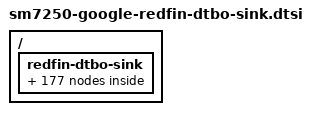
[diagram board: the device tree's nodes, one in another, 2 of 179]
// SPDX-License-Identifier: GPL-2.0-only
/*
 * Sink for the stock redfin dtbo overlays. Generated by
 * scripts/gen-dtbo-sink.py from firmware/dtbo.img; do not edit.
 *
 * Every label the 36 overlays reference (177 names, the union of
 * their __fixups__) points at an empty node under /redfin-dtbo-sink, so
 * whichever overlay the bootloader applies lands there. No compatible:
 * Linux creates no devices below it. Hand-written __symbols__ (no dtc -@):
 * real mainline nodes are never exported, so the overlay cannot touch
 * them even where label names overlap (tlmm, soc, spmi_bus, ...).
 * docs/research/mainline-boot.md, section 1.3.
 */

/ {
	redfin-dtbo-sink {
		/* Referenced so dtc gives every sink node a phandle: libfdt's
		 * fixup step needs one on each target. */
		sink-refs = <&sink_spmi_bus &sink_rpmhcc &sink_thermal_zones &sink_usb2_phy0 &sink_pm8150_l2 &sink_usb0 &sink_eud &sink_usb_qmp_dp_phy &sink_mdss_mdp &sink_CPU0 &sink_CPU6 &sink_CPU7 &sink_cpu1_isolate &sink_cpu2_isolate &sink_cpu3_isolate &sink_cpu4_isolate &sink_cpu5_isolate &sink_cpu6_isolate &sink_cpu7_isolate &sink_q6core &sink_lpass_core_hw_vote &sink_lpass_audio_hw_vote &sink_bolero &sink_intc &sink_pdc &sink_S4A &sink_BOB &sink_lito_snd &sink_stub_codec &sink_audio_apr &sink_soc &sink_spkr_1_sd_n_active &sink_spkr_1_sd_n_sleep &sink_spkr_2_sd_n_active &sink_spkr_2_sd_n_sleep &sink_wcd938x_reset_active &sink_wcd938x_reset_sleep &sink_va_cdc_dma_0_tx &sink_adsp_loader &sink_adsp_variant &sink_dai_dp &sink_dai_dp1 &sink_dai_mi2s0 &sink_dai_mi2s1 &sink_dai_mi2s2 &sink_dai_mi2s3 &sink_dai_mi2s4 &sink_dai_mi2s5 &sink_dai_pri_auxpcm &sink_dai_sec_auxpcm &sink_dai_tert_auxpcm &sink_dai_quat_auxpcm &sink_dai_quin_auxpcm &sink_dai_sen_auxpcm &sink_afe_pcm_rx &sink_afe_pcm_tx &sink_afe_proxy_rx &sink_afe_proxy_tx &sink_incall_record_rx &sink_incall_record_tx &sink_incall_music_rx &sink_incall_music_2_rx &sink_proxy_rx &sink_proxy_tx &sink_usb_audio_rx &sink_usb_audio_tx &sink_sb_7_rx &sink_sb_7_tx &sink_sb_8_tx &sink_dai_pri_tdm_rx_0 &sink_dai_pri_tdm_tx_0 &sink_dai_sec_tdm_rx_0 &sink_dai_sec_tdm_tx_0 &sink_dai_tert_tdm_rx_0 &sink_dai_tert_tdm_tx_0 &sink_dai_quat_tdm_rx_0 &sink_dai_quat_tdm_tx_0 &sink_dai_quin_tdm_rx_0 &sink_dai_quin_tdm_tx_0 &sink_dai_sen_tdm_rx_0 &sink_dai_sen_tdm_tx_0 &sink_wsa_cdc_dma_0_rx &sink_wsa_cdc_dma_0_tx &sink_wsa_cdc_dma_1_rx &sink_wsa_cdc_dma_1_tx &sink_wsa_cdc_dma_2_tx &sink_va_cdc_dma_1_tx &sink_va_cdc_dma_2_tx &sink_rx_cdc_dma_0_rx &sink_tx_cdc_dma_0_tx &sink_rx_cdc_dma_1_rx &sink_tx_cdc_dma_1_tx &sink_rx_cdc_dma_2_rx &sink_tx_cdc_dma_2_tx &sink_rx_cdc_dma_3_rx &sink_tx_cdc_dma_3_tx &sink_rx_cdc_dma_4_rx &sink_tx_cdc_dma_4_tx &sink_rx_cdc_dma_5_rx &sink_tx_cdc_dma_5_tx &sink_rx_cdc_dma_6_rx &sink_rx_cdc_dma_7_rx &sink_afe_loopback_tx &sink_qupv3_se7_i2c &sink_tlmm &sink_tdm_pri_tx &sink_qupv3_se4_spi &sink_tdm_quin_rx &sink_tdm_quin_tx &sink_qupv3_se9_i2c &sink_mdss_dsi0 &sink_mdss_dsi1 &sink_mdss_dsi_phy0 &sink_mdss_dsi_phy1 &sink_mdss_dsi0_pll &sink_mdss_dsi1_pll &sink_dispcc &sink_gcc &sink_sde_te_active &sink_sde_te_suspend &sink_L1C &sink_L16A &sink_sde_te1_active &sink_sde_te1_suspend &sink_sde_dp &sink_fsa4480 &sink_sde_dp_usbplug_cc_active &sink_sde_dp_usbplug_cc_suspend &sink_sde_rscc &sink_modem_wlan_mem &sink_reserved_memory &sink_qupv3_se7_i2c_active &sink_qupv3_se6_spi &sink_qupv3_se0_spi &sink_qupv3_se0_spi_active &sink_apps_rsc &sink_msm_gpu &sink_tsens0 &sink_aliases &sink_ufsphy_mem &sink_pm8150_l5 &sink_pm8150_l9 &sink_ufshc_mem &sink_ufs_phy_gdsc &sink_pm8150a_l7 &sink_pm8150_s4 &sink_sdhc_1 &sink_sdc1_clk_on &sink_sdc1_cmd_on &sink_sdc1_data_on &sink_sdc1_rclk_on &sink_sdc1_clk_off &sink_sdc1_cmd_off &sink_sdc1_data_off &sink_sdc1_rclk_off &sink_sdhc_2 &sink_pm8150a_l9 &sink_pm8150a_l6 &sink_sdc2_clk_on &sink_sdc2_cmd_on &sink_sdc2_data_on &sink_sdc2_cd_on &sink_sdc2_clk_off &sink_sdc2_cmd_off &sink_sdc2_data_off &sink_sdc2_cd_off &sink_msm_poweroff &sink_pm8150_l17 &sink_qupv3_se0_i2c &sink_qupv3_se11_i2c &sink_cam_cci0 &sink_titan_top_gdsc &sink_camcc &sink_cam_cci1 &sink_pm8150_l13 &sink_cci1_active &sink_cci1_suspend>;

		sink_spmi_bus: spmi-bus {};
		sink_rpmhcc: rpmhcc {};
		sink_thermal_zones: thermal-zones {};
		sink_usb2_phy0: usb2-phy0 {};
		sink_pm8150_l2: pm8150-l2 {};
		sink_usb0: usb0 {};
		sink_eud: eud {};
		sink_usb_qmp_dp_phy: usb-qmp-dp-phy {};
		sink_mdss_mdp: mdss-mdp {};
		sink_CPU0: cpu0 {};
		sink_CPU6: cpu6 {};
		sink_CPU7: cpu7 {};
		sink_cpu1_isolate: cpu1-isolate {};
		sink_cpu2_isolate: cpu2-isolate {};
		sink_cpu3_isolate: cpu3-isolate {};
		sink_cpu4_isolate: cpu4-isolate {};
		sink_cpu5_isolate: cpu5-isolate {};
		sink_cpu6_isolate: cpu6-isolate {};
		sink_cpu7_isolate: cpu7-isolate {};
		sink_q6core: q6core {};
		sink_lpass_core_hw_vote: lpass-core-hw-vote {};
		sink_lpass_audio_hw_vote: lpass-audio-hw-vote {};
		sink_bolero: bolero {};
		sink_intc: intc {};
		sink_pdc: pdc {};
		sink_S4A: s4a {};
		sink_BOB: bob {};
		sink_lito_snd: lito-snd {};
		sink_stub_codec: stub-codec {};
		sink_audio_apr: audio-apr {};
		sink_soc: soc {};
		sink_spkr_1_sd_n_active: spkr-1-sd-n-active {};
		sink_spkr_1_sd_n_sleep: spkr-1-sd-n-sleep {};
		sink_spkr_2_sd_n_active: spkr-2-sd-n-active {};
		sink_spkr_2_sd_n_sleep: spkr-2-sd-n-sleep {};
		sink_wcd938x_reset_active: wcd938x-reset-active {};
		sink_wcd938x_reset_sleep: wcd938x-reset-sleep {};
		sink_va_cdc_dma_0_tx: va-cdc-dma-0-tx {};
		sink_adsp_loader: adsp-loader {};
		sink_adsp_variant: adsp-variant {};
		sink_dai_dp: dai-dp {};
		sink_dai_dp1: dai-dp1 {};
		sink_dai_mi2s0: dai-mi2s0 {};
		sink_dai_mi2s1: dai-mi2s1 {};
		sink_dai_mi2s2: dai-mi2s2 {};
		sink_dai_mi2s3: dai-mi2s3 {};
		sink_dai_mi2s4: dai-mi2s4 {};
		sink_dai_mi2s5: dai-mi2s5 {};
		sink_dai_pri_auxpcm: dai-pri-auxpcm {};
		sink_dai_sec_auxpcm: dai-sec-auxpcm {};
		sink_dai_tert_auxpcm: dai-tert-auxpcm {};
		sink_dai_quat_auxpcm: dai-quat-auxpcm {};
		sink_dai_quin_auxpcm: dai-quin-auxpcm {};
		sink_dai_sen_auxpcm: dai-sen-auxpcm {};
		sink_afe_pcm_rx: afe-pcm-rx {};
		sink_afe_pcm_tx: afe-pcm-tx {};
		sink_afe_proxy_rx: afe-proxy-rx {};
		sink_afe_proxy_tx: afe-proxy-tx {};
		sink_incall_record_rx: incall-record-rx {};
		sink_incall_record_tx: incall-record-tx {};
		sink_incall_music_rx: incall-music-rx {};
		sink_incall_music_2_rx: incall-music-2-rx {};
		sink_proxy_rx: proxy-rx {};
		sink_proxy_tx: proxy-tx {};
		sink_usb_audio_rx: usb-audio-rx {};
		sink_usb_audio_tx: usb-audio-tx {};
		sink_sb_7_rx: sb-7-rx {};
		sink_sb_7_tx: sb-7-tx {};
		sink_sb_8_tx: sb-8-tx {};
		sink_dai_pri_tdm_rx_0: dai-pri-tdm-rx-0 {};
		sink_dai_pri_tdm_tx_0: dai-pri-tdm-tx-0 {};
		sink_dai_sec_tdm_rx_0: dai-sec-tdm-rx-0 {};
		sink_dai_sec_tdm_tx_0: dai-sec-tdm-tx-0 {};
		sink_dai_tert_tdm_rx_0: dai-tert-tdm-rx-0 {};
		sink_dai_tert_tdm_tx_0: dai-tert-tdm-tx-0 {};
		sink_dai_quat_tdm_rx_0: dai-quat-tdm-rx-0 {};
		sink_dai_quat_tdm_tx_0: dai-quat-tdm-tx-0 {};
		sink_dai_quin_tdm_rx_0: dai-quin-tdm-rx-0 {};
		sink_dai_quin_tdm_tx_0: dai-quin-tdm-tx-0 {};
		sink_dai_sen_tdm_rx_0: dai-sen-tdm-rx-0 {};
		sink_dai_sen_tdm_tx_0: dai-sen-tdm-tx-0 {};
		sink_wsa_cdc_dma_0_rx: wsa-cdc-dma-0-rx {};
		sink_wsa_cdc_dma_0_tx: wsa-cdc-dma-0-tx {};
		sink_wsa_cdc_dma_1_rx: wsa-cdc-dma-1-rx {};
		sink_wsa_cdc_dma_1_tx: wsa-cdc-dma-1-tx {};
		sink_wsa_cdc_dma_2_tx: wsa-cdc-dma-2-tx {};
		sink_va_cdc_dma_1_tx: va-cdc-dma-1-tx {};
		sink_va_cdc_dma_2_tx: va-cdc-dma-2-tx {};
		sink_rx_cdc_dma_0_rx: rx-cdc-dma-0-rx {};
		sink_tx_cdc_dma_0_tx: tx-cdc-dma-0-tx {};
		sink_rx_cdc_dma_1_rx: rx-cdc-dma-1-rx {};
		sink_tx_cdc_dma_1_tx: tx-cdc-dma-1-tx {};
		sink_rx_cdc_dma_2_rx: rx-cdc-dma-2-rx {};
		sink_tx_cdc_dma_2_tx: tx-cdc-dma-2-tx {};
		sink_rx_cdc_dma_3_rx: rx-cdc-dma-3-rx {};
		sink_tx_cdc_dma_3_tx: tx-cdc-dma-3-tx {};
		sink_rx_cdc_dma_4_rx: rx-cdc-dma-4-rx {};
		sink_tx_cdc_dma_4_tx: tx-cdc-dma-4-tx {};
		sink_rx_cdc_dma_5_rx: rx-cdc-dma-5-rx {};
		sink_tx_cdc_dma_5_tx: tx-cdc-dma-5-tx {};
		sink_rx_cdc_dma_6_rx: rx-cdc-dma-6-rx {};
		sink_rx_cdc_dma_7_rx: rx-cdc-dma-7-rx {};
		sink_afe_loopback_tx: afe-loopback-tx {};
		sink_qupv3_se7_i2c: qupv3-se7-i2c {};
		sink_tlmm: tlmm {};
		sink_tdm_pri_tx: tdm-pri-tx {};
		sink_qupv3_se4_spi: qupv3-se4-spi {};
		sink_tdm_quin_rx: tdm-quin-rx {};
		sink_tdm_quin_tx: tdm-quin-tx {};
		sink_qupv3_se9_i2c: qupv3-se9-i2c {};
		sink_mdss_dsi0: mdss-dsi0 {};
		sink_mdss_dsi1: mdss-dsi1 {};
		sink_mdss_dsi_phy0: mdss-dsi-phy0 {};
		sink_mdss_dsi_phy1: mdss-dsi-phy1 {};
		sink_mdss_dsi0_pll: mdss-dsi0-pll {};
		sink_mdss_dsi1_pll: mdss-dsi1-pll {};
		sink_dispcc: dispcc {};
		sink_gcc: gcc {};
		sink_sde_te_active: sde-te-active {};
		sink_sde_te_suspend: sde-te-suspend {};
		sink_L1C: l1c {};
		sink_L16A: l16a {};
		sink_sde_te1_active: sde-te1-active {};
		sink_sde_te1_suspend: sde-te1-suspend {};
		sink_sde_dp: sde-dp {};
		sink_fsa4480: fsa4480 {};
		sink_sde_dp_usbplug_cc_active: sde-dp-usbplug-cc-active {};
		sink_sde_dp_usbplug_cc_suspend: sde-dp-usbplug-cc-suspend {};
		sink_sde_rscc: sde-rscc {};
		sink_modem_wlan_mem: modem-wlan-mem {};
		sink_reserved_memory: reserved-memory {};
		sink_qupv3_se7_i2c_active: qupv3-se7-i2c-active {};
		sink_qupv3_se6_spi: qupv3-se6-spi {};
		sink_qupv3_se0_spi: qupv3-se0-spi {};
		sink_qupv3_se0_spi_active: qupv3-se0-spi-active {};
		sink_apps_rsc: apps-rsc {};
		sink_msm_gpu: msm-gpu {};
		sink_tsens0: tsens0 {};
		sink_aliases: aliases {};
		sink_ufsphy_mem: ufsphy-mem {};
		sink_pm8150_l5: pm8150-l5 {};
		sink_pm8150_l9: pm8150-l9 {};
		sink_ufshc_mem: ufshc-mem {};
		sink_ufs_phy_gdsc: ufs-phy-gdsc {};
		sink_pm8150a_l7: pm8150a-l7 {};
		sink_pm8150_s4: pm8150-s4 {};
		sink_sdhc_1: sdhc-1 {};
		sink_sdc1_clk_on: sdc1-clk-on {};
		sink_sdc1_cmd_on: sdc1-cmd-on {};
		sink_sdc1_data_on: sdc1-data-on {};
		sink_sdc1_rclk_on: sdc1-rclk-on {};
		sink_sdc1_clk_off: sdc1-clk-off {};
		sink_sdc1_cmd_off: sdc1-cmd-off {};
		sink_sdc1_data_off: sdc1-data-off {};
		sink_sdc1_rclk_off: sdc1-rclk-off {};
		sink_sdhc_2: sdhc-2 {};
		sink_pm8150a_l9: pm8150a-l9 {};
		sink_pm8150a_l6: pm8150a-l6 {};
		sink_sdc2_clk_on: sdc2-clk-on {};
		sink_sdc2_cmd_on: sdc2-cmd-on {};
		sink_sdc2_data_on: sdc2-data-on {};
		sink_sdc2_cd_on: sdc2-cd-on {};
		sink_sdc2_clk_off: sdc2-clk-off {};
		sink_sdc2_cmd_off: sdc2-cmd-off {};
		sink_sdc2_data_off: sdc2-data-off {};
		sink_sdc2_cd_off: sdc2-cd-off {};
		sink_msm_poweroff: msm-poweroff {};
		sink_pm8150_l17: pm8150-l17 {};
		sink_qupv3_se0_i2c: qupv3-se0-i2c {};
		sink_qupv3_se11_i2c: qupv3-se11-i2c {};
		sink_cam_cci0: cam-cci0 {};
		sink_titan_top_gdsc: titan-top-gdsc {};
		sink_camcc: camcc {};
		sink_cam_cci1: cam-cci1 {};
		sink_pm8150_l13: pm8150-l13 {};
		sink_cci1_active: cci1-active {};
		sink_cci1_suspend: cci1-suspend {};
	};

	__symbols__ {
		spmi_bus = "/redfin-dtbo-sink/spmi-bus";
		rpmhcc = "/redfin-dtbo-sink/rpmhcc";
		thermal_zones = "/redfin-dtbo-sink/thermal-zones";
		usb2_phy0 = "/redfin-dtbo-sink/usb2-phy0";
		pm8150_l2 = "/redfin-dtbo-sink/pm8150-l2";
		usb0 = "/redfin-dtbo-sink/usb0";
		eud = "/redfin-dtbo-sink/eud";
		usb_qmp_dp_phy = "/redfin-dtbo-sink/usb-qmp-dp-phy";
		mdss_mdp = "/redfin-dtbo-sink/mdss-mdp";
		CPU0 = "/redfin-dtbo-sink/cpu0";
		CPU6 = "/redfin-dtbo-sink/cpu6";
		CPU7 = "/redfin-dtbo-sink/cpu7";
		cpu1_isolate = "/redfin-dtbo-sink/cpu1-isolate";
		cpu2_isolate = "/redfin-dtbo-sink/cpu2-isolate";
		cpu3_isolate = "/redfin-dtbo-sink/cpu3-isolate";
		cpu4_isolate = "/redfin-dtbo-sink/cpu4-isolate";
		cpu5_isolate = "/redfin-dtbo-sink/cpu5-isolate";
		cpu6_isolate = "/redfin-dtbo-sink/cpu6-isolate";
		cpu7_isolate = "/redfin-dtbo-sink/cpu7-isolate";
		q6core = "/redfin-dtbo-sink/q6core";
		lpass_core_hw_vote = "/redfin-dtbo-sink/lpass-core-hw-vote";
		lpass_audio_hw_vote = "/redfin-dtbo-sink/lpass-audio-hw-vote";
		bolero = "/redfin-dtbo-sink/bolero";
		intc = "/redfin-dtbo-sink/intc";
		pdc = "/redfin-dtbo-sink/pdc";
		S4A = "/redfin-dtbo-sink/s4a";
		BOB = "/redfin-dtbo-sink/bob";
		lito_snd = "/redfin-dtbo-sink/lito-snd";
		stub_codec = "/redfin-dtbo-sink/stub-codec";
		audio_apr = "/redfin-dtbo-sink/audio-apr";
		soc = "/redfin-dtbo-sink/soc";
		spkr_1_sd_n_active = "/redfin-dtbo-sink/spkr-1-sd-n-active";
		spkr_1_sd_n_sleep = "/redfin-dtbo-sink/spkr-1-sd-n-sleep";
		spkr_2_sd_n_active = "/redfin-dtbo-sink/spkr-2-sd-n-active";
		spkr_2_sd_n_sleep = "/redfin-dtbo-sink/spkr-2-sd-n-sleep";
		wcd938x_reset_active = "/redfin-dtbo-sink/wcd938x-reset-active";
		wcd938x_reset_sleep = "/redfin-dtbo-sink/wcd938x-reset-sleep";
		va_cdc_dma_0_tx = "/redfin-dtbo-sink/va-cdc-dma-0-tx";
		adsp_loader = "/redfin-dtbo-sink/adsp-loader";
		adsp_variant = "/redfin-dtbo-sink/adsp-variant";
		dai_dp = "/redfin-dtbo-sink/dai-dp";
		dai_dp1 = "/redfin-dtbo-sink/dai-dp1";
		dai_mi2s0 = "/redfin-dtbo-sink/dai-mi2s0";
		dai_mi2s1 = "/redfin-dtbo-sink/dai-mi2s1";
		dai_mi2s2 = "/redfin-dtbo-sink/dai-mi2s2";
		dai_mi2s3 = "/redfin-dtbo-sink/dai-mi2s3";
		dai_mi2s4 = "/redfin-dtbo-sink/dai-mi2s4";
		dai_mi2s5 = "/redfin-dtbo-sink/dai-mi2s5";
		dai_pri_auxpcm = "/redfin-dtbo-sink/dai-pri-auxpcm";
		dai_sec_auxpcm = "/redfin-dtbo-sink/dai-sec-auxpcm";
		dai_tert_auxpcm = "/redfin-dtbo-sink/dai-tert-auxpcm";
		dai_quat_auxpcm = "/redfin-dtbo-sink/dai-quat-auxpcm";
		dai_quin_auxpcm = "/redfin-dtbo-sink/dai-quin-auxpcm";
		dai_sen_auxpcm = "/redfin-dtbo-sink/dai-sen-auxpcm";
		afe_pcm_rx = "/redfin-dtbo-sink/afe-pcm-rx";
		afe_pcm_tx = "/redfin-dtbo-sink/afe-pcm-tx";
		afe_proxy_rx = "/redfin-dtbo-sink/afe-proxy-rx";
		afe_proxy_tx = "/redfin-dtbo-sink/afe-proxy-tx";
		incall_record_rx = "/redfin-dtbo-sink/incall-record-rx";
		incall_record_tx = "/redfin-dtbo-sink/incall-record-tx";
		incall_music_rx = "/redfin-dtbo-sink/incall-music-rx";
		incall_music_2_rx = "/redfin-dtbo-sink/incall-music-2-rx";
		proxy_rx = "/redfin-dtbo-sink/proxy-rx";
		proxy_tx = "/redfin-dtbo-sink/proxy-tx";
		usb_audio_rx = "/redfin-dtbo-sink/usb-audio-rx";
		usb_audio_tx = "/redfin-dtbo-sink/usb-audio-tx";
		sb_7_rx = "/redfin-dtbo-sink/sb-7-rx";
		sb_7_tx = "/redfin-dtbo-sink/sb-7-tx";
		sb_8_tx = "/redfin-dtbo-sink/sb-8-tx";
		dai_pri_tdm_rx_0 = "/redfin-dtbo-sink/dai-pri-tdm-rx-0";
		dai_pri_tdm_tx_0 = "/redfin-dtbo-sink/dai-pri-tdm-tx-0";
		dai_sec_tdm_rx_0 = "/redfin-dtbo-sink/dai-sec-tdm-rx-0";
		dai_sec_tdm_tx_0 = "/redfin-dtbo-sink/dai-sec-tdm-tx-0";
		dai_tert_tdm_rx_0 = "/redfin-dtbo-sink/dai-tert-tdm-rx-0";
		dai_tert_tdm_tx_0 = "/redfin-dtbo-sink/dai-tert-tdm-tx-0";
		dai_quat_tdm_rx_0 = "/redfin-dtbo-sink/dai-quat-tdm-rx-0";
		dai_quat_tdm_tx_0 = "/redfin-dtbo-sink/dai-quat-tdm-tx-0";
		dai_quin_tdm_rx_0 = "/redfin-dtbo-sink/dai-quin-tdm-rx-0";
		dai_quin_tdm_tx_0 = "/redfin-dtbo-sink/dai-quin-tdm-tx-0";
		dai_sen_tdm_rx_0 = "/redfin-dtbo-sink/dai-sen-tdm-rx-0";
		dai_sen_tdm_tx_0 = "/redfin-dtbo-sink/dai-sen-tdm-tx-0";
		wsa_cdc_dma_0_rx = "/redfin-dtbo-sink/wsa-cdc-dma-0-rx";
		wsa_cdc_dma_0_tx = "/redfin-dtbo-sink/wsa-cdc-dma-0-tx";
		wsa_cdc_dma_1_rx = "/redfin-dtbo-sink/wsa-cdc-dma-1-rx";
		wsa_cdc_dma_1_tx = "/redfin-dtbo-sink/wsa-cdc-dma-1-tx";
		wsa_cdc_dma_2_tx = "/redfin-dtbo-sink/wsa-cdc-dma-2-tx";
		va_cdc_dma_1_tx = "/redfin-dtbo-sink/va-cdc-dma-1-tx";
		va_cdc_dma_2_tx = "/redfin-dtbo-sink/va-cdc-dma-2-tx";
		rx_cdc_dma_0_rx = "/redfin-dtbo-sink/rx-cdc-dma-0-rx";
		tx_cdc_dma_0_tx = "/redfin-dtbo-sink/tx-cdc-dma-0-tx";
		rx_cdc_dma_1_rx = "/redfin-dtbo-sink/rx-cdc-dma-1-rx";
		tx_cdc_dma_1_tx = "/redfin-dtbo-sink/tx-cdc-dma-1-tx";
		rx_cdc_dma_2_rx = "/redfin-dtbo-sink/rx-cdc-dma-2-rx";
		tx_cdc_dma_2_tx = "/redfin-dtbo-sink/tx-cdc-dma-2-tx";
		rx_cdc_dma_3_rx = "/redfin-dtbo-sink/rx-cdc-dma-3-rx";
		tx_cdc_dma_3_tx = "/redfin-dtbo-sink/tx-cdc-dma-3-tx";
		rx_cdc_dma_4_rx = "/redfin-dtbo-sink/rx-cdc-dma-4-rx";
		tx_cdc_dma_4_tx = "/redfin-dtbo-sink/tx-cdc-dma-4-tx";
		rx_cdc_dma_5_rx = "/redfin-dtbo-sink/rx-cdc-dma-5-rx";
		tx_cdc_dma_5_tx = "/redfin-dtbo-sink/tx-cdc-dma-5-tx";
		rx_cdc_dma_6_rx = "/redfin-dtbo-sink/rx-cdc-dma-6-rx";
		rx_cdc_dma_7_rx = "/redfin-dtbo-sink/rx-cdc-dma-7-rx";
		afe_loopback_tx = "/redfin-dtbo-sink/afe-loopback-tx";
		qupv3_se7_i2c = "/redfin-dtbo-sink/qupv3-se7-i2c";
		tlmm = "/redfin-dtbo-sink/tlmm";
		tdm_pri_tx = "/redfin-dtbo-sink/tdm-pri-tx";
		qupv3_se4_spi = "/redfin-dtbo-sink/qupv3-se4-spi";
		tdm_quin_rx = "/redfin-dtbo-sink/tdm-quin-rx";
		tdm_quin_tx = "/redfin-dtbo-sink/tdm-quin-tx";
		qupv3_se9_i2c = "/redfin-dtbo-sink/qupv3-se9-i2c";
		mdss_dsi0 = "/redfin-dtbo-sink/mdss-dsi0";
		mdss_dsi1 = "/redfin-dtbo-sink/mdss-dsi1";
		mdss_dsi_phy0 = "/redfin-dtbo-sink/mdss-dsi-phy0";
		mdss_dsi_phy1 = "/redfin-dtbo-sink/mdss-dsi-phy1";
		mdss_dsi0_pll = "/redfin-dtbo-sink/mdss-dsi0-pll";
		mdss_dsi1_pll = "/redfin-dtbo-sink/mdss-dsi1-pll";
		dispcc = "/redfin-dtbo-sink/dispcc";
		gcc = "/redfin-dtbo-sink/gcc";
		sde_te_active = "/redfin-dtbo-sink/sde-te-active";
		sde_te_suspend = "/redfin-dtbo-sink/sde-te-suspend";
		L1C = "/redfin-dtbo-sink/l1c";
		L16A = "/redfin-dtbo-sink/l16a";
		sde_te1_active = "/redfin-dtbo-sink/sde-te1-active";
		sde_te1_suspend = "/redfin-dtbo-sink/sde-te1-suspend";
		sde_dp = "/redfin-dtbo-sink/sde-dp";
		fsa4480 = "/redfin-dtbo-sink/fsa4480";
		sde_dp_usbplug_cc_active = "/redfin-dtbo-sink/sde-dp-usbplug-cc-active";
		sde_dp_usbplug_cc_suspend = "/redfin-dtbo-sink/sde-dp-usbplug-cc-suspend";
		sde_rscc = "/redfin-dtbo-sink/sde-rscc";
		modem_wlan_mem = "/redfin-dtbo-sink/modem-wlan-mem";
		reserved_memory = "/redfin-dtbo-sink/reserved-memory";
		qupv3_se7_i2c_active = "/redfin-dtbo-sink/qupv3-se7-i2c-active";
		qupv3_se6_spi = "/redfin-dtbo-sink/qupv3-se6-spi";
		qupv3_se0_spi = "/redfin-dtbo-sink/qupv3-se0-spi";
		qupv3_se0_spi_active = "/redfin-dtbo-sink/qupv3-se0-spi-active";
		apps_rsc = "/redfin-dtbo-sink/apps-rsc";
		msm_gpu = "/redfin-dtbo-sink/msm-gpu";
		tsens0 = "/redfin-dtbo-sink/tsens0";
		aliases = "/redfin-dtbo-sink/aliases";
		ufsphy_mem = "/redfin-dtbo-sink/ufsphy-mem";
		pm8150_l5 = "/redfin-dtbo-sink/pm8150-l5";
		pm8150_l9 = "/redfin-dtbo-sink/pm8150-l9";
		ufshc_mem = "/redfin-dtbo-sink/ufshc-mem";
		ufs_phy_gdsc = "/redfin-dtbo-sink/ufs-phy-gdsc";
		pm8150a_l7 = "/redfin-dtbo-sink/pm8150a-l7";
		pm8150_s4 = "/redfin-dtbo-sink/pm8150-s4";
		sdhc_1 = "/redfin-dtbo-sink/sdhc-1";
		sdc1_clk_on = "/redfin-dtbo-sink/sdc1-clk-on";
		sdc1_cmd_on = "/redfin-dtbo-sink/sdc1-cmd-on";
		sdc1_data_on = "/redfin-dtbo-sink/sdc1-data-on";
		sdc1_rclk_on = "/redfin-dtbo-sink/sdc1-rclk-on";
		sdc1_clk_off = "/redfin-dtbo-sink/sdc1-clk-off";
		sdc1_cmd_off = "/redfin-dtbo-sink/sdc1-cmd-off";
		sdc1_data_off = "/redfin-dtbo-sink/sdc1-data-off";
		sdc1_rclk_off = "/redfin-dtbo-sink/sdc1-rclk-off";
		sdhc_2 = "/redfin-dtbo-sink/sdhc-2";
		pm8150a_l9 = "/redfin-dtbo-sink/pm8150a-l9";
		pm8150a_l6 = "/redfin-dtbo-sink/pm8150a-l6";
		sdc2_clk_on = "/redfin-dtbo-sink/sdc2-clk-on";
		sdc2_cmd_on = "/redfin-dtbo-sink/sdc2-cmd-on";
		sdc2_data_on = "/redfin-dtbo-sink/sdc2-data-on";
		sdc2_cd_on = "/redfin-dtbo-sink/sdc2-cd-on";
		sdc2_clk_off = "/redfin-dtbo-sink/sdc2-clk-off";
		sdc2_cmd_off = "/redfin-dtbo-sink/sdc2-cmd-off";
		sdc2_data_off = "/redfin-dtbo-sink/sdc2-data-off";
		sdc2_cd_off = "/redfin-dtbo-sink/sdc2-cd-off";
		msm_poweroff = "/redfin-dtbo-sink/msm-poweroff";
		pm8150_l17 = "/redfin-dtbo-sink/pm8150-l17";
		qupv3_se0_i2c = "/redfin-dtbo-sink/qupv3-se0-i2c";
		qupv3_se11_i2c = "/redfin-dtbo-sink/qupv3-se11-i2c";
		cam_cci0 = "/redfin-dtbo-sink/cam-cci0";
		titan_top_gdsc = "/redfin-dtbo-sink/titan-top-gdsc";
		camcc = "/redfin-dtbo-sink/camcc";
		cam_cci1 = "/redfin-dtbo-sink/cam-cci1";
		pm8150_l13 = "/redfin-dtbo-sink/pm8150-l13";
		cci1_active = "/redfin-dtbo-sink/cci1-active";
		cci1_suspend = "/redfin-dtbo-sink/cci1-suspend";
	};
};
